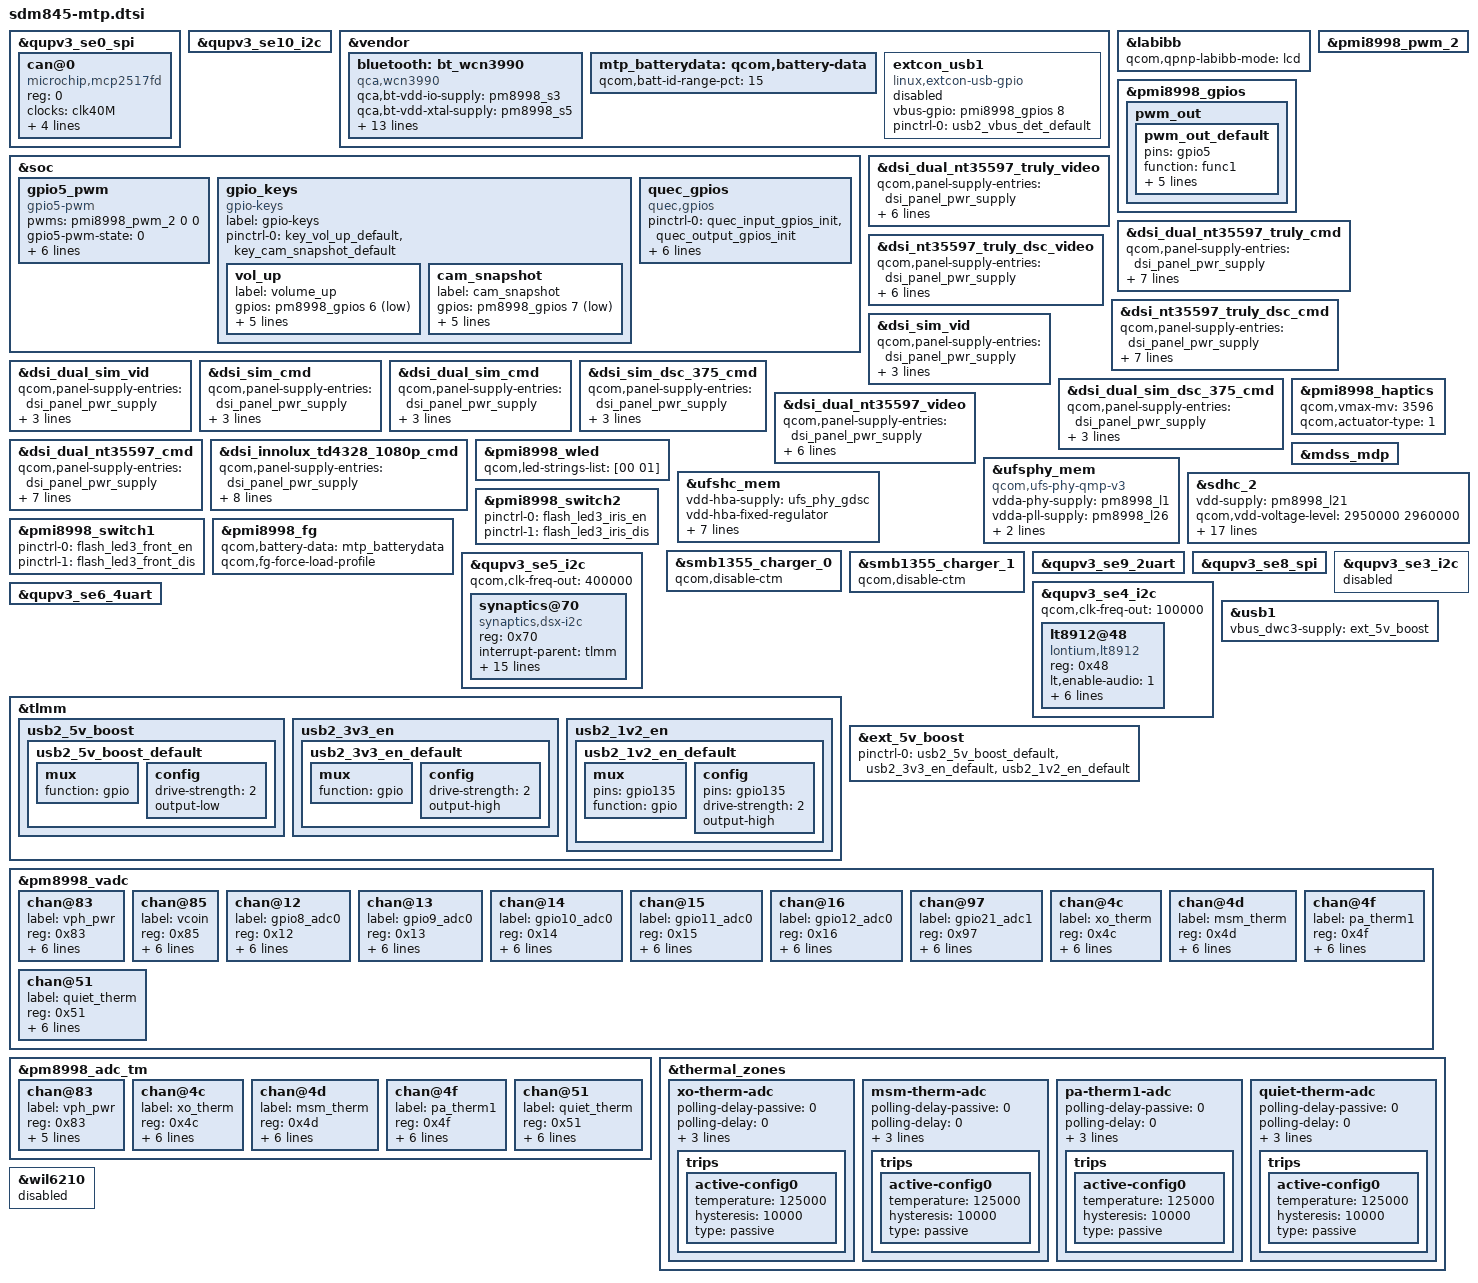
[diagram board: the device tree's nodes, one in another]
/* Copyright (c) 2016-2019, The Linux Foundation. All rights reserved.
 *
 * This program is free software; you can redistribute it and/or modify
 * it under the terms of the GNU General Public License version 2 and
 * only version 2 as published by the Free Software Foundation.
 *
 * This program is distributed in the hope that it will be useful,
 * but WITHOUT ANY WARRANTY; without even the implied warranty of
 * MERCHANTABILITY or FITNESS FOR A PARTICULAR PURPOSE.  See the
 * GNU General Public License for more details.
 */

#include <dt-bindings/gpio/gpio.h>
#include "sdm845-pmic-overlay.dtsi"
#include "sdm845-pinctrl-overlay.dtsi"
#include "sdm845-camera-sensor-mtp.dtsi"

&qupv3_se0_spi {
	status = "ok";
	can@0 {
		compatible = "microchip,mcp2517fd";
		reg = <0>;
		clocks = <&clk40M>;
		interrupt-parent = <&tlmm>;
		interrupts = <34 0>;
		interrupt-names = "can_irq";
		spi-max-frequency = <10000000>;
		gpio-controller;
		status = "okay";
	};
};

&qupv3_se10_i2c {
#include "smb1355.dtsi"
};

&vendor {
	bluetooth: bt_wcn3990 {
		compatible = "qca,wcn3990";
		qca,bt-vdd-io-supply = <&pm8998_s3>;
		qca,bt-vdd-xtal-supply = <&pm8998_s5>;
		qca,bt-vdd-core-supply = <&pm8998_l7>;
		qca,bt-vdd-pa-supply = <&pm8998_l17>;
		qca,bt-vdd-ldo-supply = <&pm8998_l25>;

		qca,bt-vdd-io-voltage-level = <1352000 1352000>;
		qca,bt-vdd-xtal-voltage-level = <2040000 2040000>;
		qca,bt-vdd-core-voltage-level = <1800000 1800000>;
		qca,bt-vdd-pa-voltage-level = <1304000 1304000>;
		qca,bt-vdd-ldo-voltage-level = <3312000 3312000>;

		qca,bt-vdd-io-current-level = <1>; /* LPM/PFM */
		qca,bt-vdd-xtal-current-level = <1>; /* LPM/PFM */
		qca,bt-vdd-core-current-level = <1>; /* LPM/PFM */
		qca,bt-vdd-pa-current-level = <1>; /* LPM/PFM */
		qca,bt-vdd-ldo-current-level = <1>; /* LPM/PFM */
	};
};

&soc {
	//zhounengwen@163.com begin
	gpio5_pwm {
		compatible = "gpio5-pwm";
		pwms = <&pmi8998_pwm_2 0 0>;
		gpio5-pwm-state = <0>;
		gpio5-pwm-duty-ns = <10000>;
		gpio5-pwm-period-ns = <50000>;
		qcom,fan-en-gpio = <&tlmm 44 0>;
		qcom,fan-fg-gpio = <&tlmm 30 0x2004>;
		pinctrl-names = "default";
		pinctrl-0 = <&pwm_out_default>;
		pinctrl-1 = <&fg_int_default>;
	};
	//zhounengwen@163.com end
	gpio_keys {
		compatible = "gpio-keys";
		label = "gpio-keys";

		pinctrl-names = "default";
		pinctrl-0 = <&key_vol_up_default
			     &key_cam_snapshot_default>;

		vol_up {
			label = "volume_up";
			gpios = <&pm8998_gpios 6 GPIO_ACTIVE_LOW>;
			linux,input-type = <1>;
			linux,code = <115>;
			gpio-key,wakeup;
			debounce-interval = <15>;
			linux,can-disable;
		};

		cam_snapshot {
			label = "cam_snapshot";
			gpios = <&pm8998_gpios 7 GPIO_ACTIVE_LOW>;
			linux,input-type = <1>;
			linux,code = <766>;
			gpio-key,wakeup;
			debounce-interval = <15>;
			linux,can-disable;
		};

		/*cam_focus {
			label = "cam_focus";
			gpios = <&pm8998_gpios 8 GPIO_ACTIVE_LOW>;
			linux,input-type = <1>;
			linux,code = <528>;
			gpio-key,wakeup;
			debounce-interval = <15>;
			linux,can-disable;
		};*/
	};
	
	quec_gpios {
		compatible = "quec,gpios";
		pinctrl-names = "default";
		pinctrl-0 = <&quec_input_gpios_init 
						&quec_output_gpios_init>;
		gpios = <&tlmm 0 0>,
			<&tlmm 3 0>,
			<&tlmm 7 1>,
			<&tlmm 22 0>,
			<&tlmm 24 0>,
			<&tlmm 25 1>,
			<&tlmm 26 0>,
			<&tlmm 40 0>,
			<&tlmm 41 0>,
			<&tlmm 49 0>,
			<&tlmm 52 0>,
			<&tlmm 87 1>,
			<&tlmm 91 0>,
			<&tlmm 92 0>,
			<&tlmm 95 0>,
			<&tlmm 96 0>,
			<&tlmm 116 0>,
			<&tlmm 122 0>,
			<&tlmm 124 0>,
			<&tlmm 128 0>,
			<&tlmm 129 1>;
	};
};

&labibb {
	status = "ok";
	qcom,qpnp-labibb-mode = "lcd";
};
//zhounengwen@163.com begin
&pmi8998_gpios {
    pwm_out {
        pwm_out_default: pwm_out_default {
            pins = "gpio5";
            function = "func1";
            bias-disable;
            power-source = <0>;
            output-low;
            qcom,drive-strength = <3>;
            drive-push-pull;
        };
    };
};

&pmi8998_pwm_2 {
    status = "okay";
    //qcom,force-pwm-size = <9>;
    //qcom,mode-select = <0>;
    //qcom,period = <100000>;
    //qcom,pwm {
    //    qcom,duty = <50000>;
    //    label = "pwm";
    //};
};
//zhounengwen@163.com end

&dsi_dual_nt35597_truly_video {
	qcom,panel-supply-entries = <&dsi_panel_pwr_supply>;
	qcom,mdss-dsi-bl-pmic-control-type = "bl_ctrl_wled";
	qcom,mdss-dsi-bl-min-level = <1>;
	qcom,mdss-dsi-bl-max-level = <4095>;
	qcom,mdss-dsi-mode-sel-gpio-state = "dual_port";
	//qcom,panel-mode-gpio = <&tlmm 52 0>;
	qcom,platform-reset-gpio = <&tlmm 6 0>;
};

&dsi_dual_nt35597_truly_cmd {
	qcom,panel-supply-entries = <&dsi_panel_pwr_supply>;
	qcom,mdss-dsi-bl-pmic-control-type = "bl_ctrl_wled";
	qcom,mdss-dsi-bl-min-level = <1>;
	qcom,mdss-dsi-bl-max-level = <4095>;
	qcom,mdss-dsi-mode-sel-gpio-state = "dual_port";
	//qcom,panel-mode-gpio = <&tlmm 52 0>;
	qcom,platform-reset-gpio = <&tlmm 6 0>;
	qcom,platform-te-gpio = <&tlmm 10 0>;
};

&dsi_nt35597_truly_dsc_video {
	qcom,panel-supply-entries = <&dsi_panel_pwr_supply>;
	qcom,mdss-dsi-bl-pmic-control-type = "bl_ctrl_wled";
	qcom,mdss-dsi-bl-min-level = <1>;
	qcom,mdss-dsi-bl-max-level = <4095>;
	qcom,mdss-dsi-mode-sel-gpio-state = "single_port";
	//qcom,panel-mode-gpio = <&tlmm 52 0>;
	qcom,platform-reset-gpio = <&tlmm 6 0>;
};

&dsi_nt35597_truly_dsc_cmd {
	qcom,panel-supply-entries = <&dsi_panel_pwr_supply>;
	qcom,mdss-dsi-bl-pmic-control-type = "bl_ctrl_wled";
	qcom,mdss-dsi-bl-min-level = <1>;
	qcom,mdss-dsi-bl-max-level = <4095>;
	qcom,mdss-dsi-mode-sel-gpio-state = "single_port";
	//qcom,panel-mode-gpio = <&tlmm 52 0>;
	qcom,platform-reset-gpio = <&tlmm 6 0>;
	qcom,platform-te-gpio = <&tlmm 10 0>;
};

&dsi_sim_vid {
	qcom,panel-supply-entries = <&dsi_panel_pwr_supply>;
	qcom,mdss-dsi-bl-pmic-control-type = "bl_ctrl_wled";
	qcom,platform-reset-gpio = <&tlmm 6 0>;
};

&dsi_dual_sim_vid {
	qcom,panel-supply-entries = <&dsi_panel_pwr_supply>;
	qcom,mdss-dsi-bl-pmic-control-type = "bl_ctrl_wled";
	qcom,platform-reset-gpio = <&tlmm 6 0>;
};

&dsi_sim_cmd {
	qcom,panel-supply-entries = <&dsi_panel_pwr_supply>;
	qcom,mdss-dsi-bl-pmic-control-type = "bl_ctrl_wled";
	qcom,platform-reset-gpio = <&tlmm 6 0>;
};

&dsi_dual_sim_cmd {
	qcom,panel-supply-entries = <&dsi_panel_pwr_supply>;
	qcom,mdss-dsi-bl-pmic-control-type = "bl_ctrl_wled";
	qcom,platform-reset-gpio = <&tlmm 6 0>;
};

&dsi_sim_dsc_375_cmd {
	qcom,panel-supply-entries = <&dsi_panel_pwr_supply>;
	qcom,mdss-dsi-bl-pmic-control-type = "bl_ctrl_wled";
	qcom,platform-reset-gpio = <&tlmm 6 0>;
};

&dsi_dual_sim_dsc_375_cmd {
	qcom,panel-supply-entries = <&dsi_panel_pwr_supply>;
	qcom,mdss-dsi-bl-pmic-control-type = "bl_ctrl_wled";
	qcom,platform-reset-gpio = <&tlmm 6 0>;
};

&dsi_dual_nt35597_video {
	qcom,panel-supply-entries = <&dsi_panel_pwr_supply>;
	qcom,mdss-dsi-bl-pmic-control-type = "bl_ctrl_wled";
	qcom,mdss-dsi-bl-min-level = <1>;
	qcom,mdss-dsi-bl-max-level = <4095>;
	qcom,mdss-dsi-mode-sel-gpio-state = "dual_port";
	//qcom,panel-mode-gpio = <&tlmm 52 0>;
	qcom,platform-reset-gpio = <&tlmm 6 0>;
};

&dsi_dual_nt35597_cmd {
	qcom,panel-supply-entries = <&dsi_panel_pwr_supply>;
	qcom,mdss-dsi-bl-pmic-control-type = "bl_ctrl_wled";
	qcom,mdss-dsi-bl-min-level = <1>;
	qcom,mdss-dsi-bl-max-level = <4095>;
	qcom,mdss-dsi-mode-sel-gpio-state = "dual_port";
	//qcom,panel-mode-gpio = <&tlmm 52 0>;
	qcom,platform-reset-gpio = <&tlmm 6 0>;
	qcom,platform-te-gpio = <&tlmm 10 0>;
};

&dsi_innolux_td4328_1080p_cmd {
	qcom,panel-supply-entries = <&dsi_panel_pwr_supply>;
	qcom,mdss-dsi-bl-pmic-control-type = "bl_ctrl_wled";
	qcom,mdss-dsi-bl-min-level = <1>;
	qcom,mdss-dsi-bl-max-level = <4095>;
	qcom,mdss-dsi-mode-sel-gpio-state = "single_port";
	qcom,5v-boost-gpio = <&tlmm 120 0>;
	qcom,platform-reset-gpio = <&tlmm 6 0>;
	qcom,platform-te-gpio = <&tlmm 10 0>;
};
/*
&dsi_nt35597_truly_dsc_cmd_display {
	qcom,dsi-display-active;
};
*/
&pmi8998_wled {
	status = "okay";
	qcom,led-strings-list = [00 01];
};

&pmi8998_haptics {
	qcom,vmax-mv = <3596>;
	//qcom,lra-auto-mode;
	qcom,actuator-type = <1>;
	status = "okay";
};

&mdss_mdp {
	#cooling-cells = <2>;
};

&ufsphy_mem {
	compatible = "qcom,ufs-phy-qmp-v3";

	vdda-phy-supply = <&pm8998_l1>; /* 0.88v */
	vdda-pll-supply = <&pm8998_l26>; /* 1.2v */
	vdda-phy-max-microamp = <62900>;
	vdda-pll-max-microamp = <18300>;

	status = "ok";
};

&ufshc_mem {
	vdd-hba-supply = <&ufs_phy_gdsc>;
	vdd-hba-fixed-regulator;
	vcc-supply = <&pm8998_l20>;
	vcc-voltage-level = <2950000 2960000>;
	vccq2-supply = <&pm8998_s4>;
	vcc-max-microamp = <600000>;
	vccq2-max-microamp = <600000>;

	qcom,vddp-ref-clk-supply = <&pm8998_l2>;
	qcom,vddp-ref-clk-max-microamp = <100>;

	status = "ok";
};

&sdhc_2 {
	vdd-supply = <&pm8998_l21>;
	qcom,vdd-voltage-level = <2950000 2960000>;
	qcom,vdd-current-level = <200 800000>;

	vdd-io-supply = <&pm8998_l13>;
	qcom,vdd-io-voltage-level = <1808000 2960000>;
	qcom,vdd-io-current-level = <200 22000>;

	pinctrl-names = "active", "sleep", "ds_400KHz",
			"ds_50MHz", "ds_100MHz", "ds_200MHz";
	pinctrl-0 = <&sdc2_clk_on  &sdc2_cmd_on &sdc2_data_on &storage_cd>;
	pinctrl-1 = <&sdc2_clk_off &sdc2_cmd_off &sdc2_data_off &storage_cd>;
	pinctrl-2 = <&sdc2_clk_ds_400KHz
			&sdc2_cmd_ds_400KHz &sdc2_data_ds_400KHz>;
	pinctrl-3 = <&sdc2_clk_ds_50MHz
			&sdc2_cmd_ds_50MHz &sdc2_data_ds_50MHz>;
	pinctrl-4 = <&sdc2_clk_ds_100MHz
			&sdc2_cmd_ds_100MHz &sdc2_data_ds_100MHz>;
	pinctrl-5 = <&sdc2_clk_ds_200MHz
			&sdc2_cmd_ds_200MHz &sdc2_data_ds_200MHz>;

	cd-gpios = <&tlmm 126 GPIO_ACTIVE_LOW>;

	status = "ok";
};

&pmi8998_switch1 {
	pinctrl-names = "led_enable", "led_disable";
	pinctrl-0 = <&flash_led3_front_en>;
	pinctrl-1 = <&flash_led3_front_dis>;
};

&pmi8998_switch2 {
	pinctrl-names = "led_enable", "led_disable";
	pinctrl-0 = <&flash_led3_iris_en>;
	pinctrl-1 = <&flash_led3_iris_dis>;
};

&vendor {
	mtp_batterydata: qcom,battery-data {
		qcom,batt-id-range-pct = <15>;
		//#include "fg-gen3-batterydata-itech-3000mah.dtsi"
		//#include "fg-gen3-batterydata-ascent-3450mah.dtsi"
		//#include "fg-gen3-batterydata-chijin-5000mah.dtsi"
		#include "fg-gen3-batterydata-chijin-6600mah.dtsi"
	};

	extcon_usb1: extcon_usb1 {
		compatible = "linux,extcon-usb-gpio";
		vbus-gpio = <&pmi8998_gpios 8 GPIO_ACTIVE_HIGH>;

		pinctrl-names = "default";
		pinctrl-0 = <&usb2_vbus_det_default>;
		status = "disabled";
	};
};

&pmi8998_fg {
	qcom,battery-data = <&mtp_batterydata>;
	qcom,fg-force-load-profile;
};

&smb1355_charger_0 {
	status = "ok";
	qcom,disable-ctm;
};

&smb1355_charger_1 {
	status = "ok";
	qcom,disable-ctm;
};

&qupv3_se9_2uart {
	status = "ok";
};

&qupv3_se8_spi {
	status = "ok";
};

/*
&qupv3_se7_i2c {
	status = "ok";
	ads7830@48 {
		compatible = "ads7830";
		reg = <0x48>;
	};
};
*/
&qupv3_se3_i2c {
	status = "disabled";
	/*nq@28 {
		compatible = "qcom,nq-nci";
		reg = <0x28>;
		qcom,nq-irq = <&tlmm 63 0x00>;
		qcom,nq-ven = <&tlmm 12 0x00>;
		qcom,nq-firm = <&tlmm 62 0x00>;
		qcom,nq-clkreq = <&pm8998_gpios 21 0x00>;
		//qcom,nq-esepwr = <&tlmm 116 0x00>;
		interrupt-parent = <&tlmm>;
		interrupts = <63 0>;
		interrupt-names = "nfc_irq";
		pinctrl-names = "nfc_active", "nfc_suspend";
		pinctrl-0 = <&nfc_int_active
			     &nfc_enable_active
			     &nfc_clk_default>;
		pinctrl-1 = <&nfc_int_suspend &nfc_enable_suspend>;
	};*/
};

&qupv3_se5_i2c {
	status = "ok";
	qcom,clk-freq-out = <400000>;
	synaptics@70 {
		compatible = "synaptics,dsx-i2c";
		reg = <0x70>;
		interrupt-parent = <&tlmm>;
		interrupts = <125 0x2>;
		pinctrl-names = "pmx_ts_active", "pmx_ts_suspend";
		pinctrl-0 = <&ts_int_active &ts_reset_active>;
		pinctrl-1 = <&ts_int_suspend &ts_reset_suspend>;
		vdd_ana-supply = <&pm8998_l28>;
		vcc_i2c-supply  = <&pm8998_l14>;
		synaptics,pwr-reg-name = "vdd_ana";
		synaptics,bus-reg-name = "vcc_i2c";
		synaptics,ub-i2c-addr = <0x20>;
		/* IRQF_ONESHOT | IRQF_TRIGGER_LOW */
		synaptics,irq-gpio = <&tlmm 125 0x2008>;
		synaptics,irq-on-state = <0>;
		synaptics,reset-gpio = <&tlmm 104 0>;	//hrb
		synaptics,power-delay-ms = <200>;
		synaptics,reset-delay-ms = <200>;
		synaptics,reset-on-state = <0>;
		synaptics,reset-active-ms = <20>;

	};
};
//zhounengwen@163.com begin
&qupv3_se4_i2c {
	status = "ok";
	qcom,clk-freq-out = <100000>;
	lt8912@48 {
		compatible = "lontium,lt8912";
		status = "okay";
		reg = <0x48>;
		lt,enable-audio = <1>;
		lt,pwren-gpio = <&tlmm 8 0x00>;
		lt,reset-gpio = <&tlmm 12 0x00>;
		lt,hdmien-gpio = <&tlmm 13 0x00>;
		lt,hdmidet-gpio = <&tlmm 121 0x00>;
		pinctrl-names = "hdmidet_active","hdmidet_suspend";
		pinctrl-0 = <&hdmi_det_active>;
		pinctrl-1 = <&hdmi_det_suspend>;
		//lt,hpd-gpio = <&tlmm 9 0x00>;
		//interrupt-parent = <&tlmm>;
		//interrupts = <9 0>;
		//interrupt-names = "hdmi_hpd_irq1";
	};
};
//zhounengwen@163.com end
&qupv3_se10_i2c {
	status = "ok";
};

&qupv3_se6_4uart {
	status = "ok";
};

&tlmm {
	usb2_5v_boost {
		usb2_5v_boost_default: usb2_5v_boost_default  {
			mux {
				//pins = "gpio129";
				function = "gpio";
			};

			config {
				//pins = "gpio129";         
				drive-strength = <2>;  
				output-low;  
			};
		};
	};
	
	usb2_3v3_en {
		usb2_3v3_en_default: usb2_3v3_en_default  {
			mux {
				//pins = "gpio128";
				function = "gpio";
			};

			config {
				//pins = "gpio128";         
				drive-strength = <2>;  
				output-high;  
			};
		};
	};

	usb2_1v2_en {
		usb2_1v2_en_default: usb2_1v2_en_default  {
			mux {
				pins = "gpio135";
				function = "gpio";
			};

			config {
				pins = "gpio135";         
				drive-strength = <2>;  
				output-high;  
			};
		};
	};
};

&ext_5v_boost {
	status = "ok";
	//gpio = <&tlmm 129 GPIO_ACTIVE_HIGH>;
	pinctrl-names = "default";
	pinctrl-0 = <&usb2_5v_boost_default
	             &usb2_3v3_en_default
				 &usb2_1v2_en_default>;
};

&usb1 {
     status = "ok";
	//extcon = <&extcon_usb1>;
	vbus_dwc3-supply = <&ext_5v_boost>;
};

&pm8998_vadc {
	chan@83 {
		label = "vph_pwr";
		reg = <0x83>;
		qcom,decimation = <2>;
		qcom,pre-div-channel-scaling = <1>;
		qcom,calibration-type = "absolute";
		qcom,scale-function = <0>;
		qcom,hw-settle-time = <0>;
		qcom,fast-avg-setup = <0>;
	};

	chan@85 {
		label = "vcoin";
		reg = <0x85>;
		qcom,decimation = <2>;
		qcom,pre-div-channel-scaling = <1>;
		qcom,calibration-type = "absolute";
		qcom,scale-function = <0>;
		qcom,hw-settle-time = <0>;
		qcom,fast-avg-setup = <0>;
	};

	chan@12 {
		label = "gpio8_adc0";
		reg = <0x12>;
		qcom,decimation = <0>;
		qcom,pre-div-channel-scaling = <0>;
		qcom,calibration-type = "absolute";
		qcom,scale-function = <0>;
		qcom,hw-settle-time = <0>;
		qcom,fast-avg-setup = <0>;
	};
	
	chan@13 {
		label = "gpio9_adc0";
		reg = <0x13>;
		qcom,decimation = <0>;
		qcom,pre-div-channel-scaling = <0>;
		qcom,calibration-type = "absolute";
		qcom,scale-function = <0>;
		qcom,hw-settle-time = <0>;
		qcom,fast-avg-setup = <0>;
	};
	
	chan@14 {
		label = "gpio10_adc0";
		reg = <0x14>;
		qcom,decimation = <0>;
		qcom,pre-div-channel-scaling = <0>;
		qcom,calibration-type = "absolute";
		qcom,scale-function = <0>;
		qcom,hw-settle-time = <0>;
		qcom,fast-avg-setup = <0>;
	};
	
	chan@15 {
		label = "gpio11_adc0";
		reg = <0x15>;
		qcom,decimation = <0>;
		qcom,pre-div-channel-scaling = <0>;
		qcom,calibration-type = "absolute";
		qcom,scale-function = <0>;
		qcom,hw-settle-time = <0>;
		qcom,fast-avg-setup = <0>;
	};
	
	chan@16 {
		label = "gpio12_adc0";
		reg = <0x16>;
		qcom,decimation = <0>;
		qcom,pre-div-channel-scaling = <0>;
		qcom,calibration-type = "absolute";
		qcom,scale-function = <0>;
		qcom,hw-settle-time = <0>;
		qcom,fast-avg-setup = <0>;
	};
	
	chan@97 {
		label = "gpio21_adc1";
		reg = <0x97>;
		qcom,decimation = <0>;
		qcom,pre-div-channel-scaling = <1>;
		qcom,calibration-type = "absolute";
		qcom,scale-function = <0>;
		qcom,hw-settle-time = <0>;
		qcom,fast-avg-setup = <0>;
	};
	
	chan@4c {
		label = "xo_therm";
		reg = <0x4c>;
		qcom,decimation = <2>;
		qcom,pre-div-channel-scaling = <0>;
		qcom,calibration-type = "ratiometric";
		qcom,scale-function = <4>;
		qcom,hw-settle-time = <2>;
		qcom,fast-avg-setup = <0>;
	};

	chan@4d {
		label = "msm_therm";
		reg = <0x4d>;
		qcom,decimation = <2>;
		qcom,pre-div-channel-scaling = <0>;
		qcom,calibration-type = "ratiometric";
		qcom,scale-function = <2>;
		qcom,hw-settle-time = <2>;
		qcom,fast-avg-setup = <0>;
	};

	chan@4f {
		label = "pa_therm1";
		reg = <0x4f>;
		qcom,decimation = <2>;
		qcom,pre-div-channel-scaling = <0>;
		qcom,calibration-type = "ratiometric";
		qcom,scale-function = <2>;
		qcom,hw-settle-time = <2>;
		qcom,fast-avg-setup = <0>;
	};

	chan@51 {
		label = "quiet_therm";
		reg = <0x51>;
		qcom,decimation = <2>;
		qcom,pre-div-channel-scaling = <0>;
		qcom,calibration-type = "ratiometric";
		qcom,scale-function = <2>;
		qcom,hw-settle-time = <2>;
		qcom,fast-avg-setup = <0>;
	};
};

&pm8998_adc_tm {
	chan@83 {
		label = "vph_pwr";
		reg = <0x83>;
		qcom,pre-div-channel-scaling = <1>;
		qcom,calibration-type = "absolute";
		qcom,scale-function = <0>;
		qcom,hw-settle-time = <0>;
		qcom,btm-channel-number = <0x60>;
	};

	chan@4c {
		label = "xo_therm";
		reg = <0x4c>;
		qcom,pre-div-channel-scaling = <0>;
		qcom,calibration-type = "ratiometric";
		qcom,scale-function = <4>;
		qcom,hw-settle-time = <2>;
		qcom,btm-channel-number = <0x68>;
		qcom,thermal-node;
	};

	chan@4d {
		label = "msm_therm";
		reg = <0x4d>;
		qcom,pre-div-channel-scaling = <0>;
		qcom,calibration-type = "ratiometric";
		qcom,scale-function = <2>;
		qcom,hw-settle-time = <2>;
		qcom,btm-channel-number = <0x70>;
		qcom,thermal-node;
	};

	chan@4f {
		label = "pa_therm1";
		reg = <0x4f>;
		qcom,pre-div-channel-scaling = <0>;
		qcom,calibration-type = "ratiometric";
		qcom,scale-function = <2>;
		qcom,hw-settle-time = <2>;
		qcom,btm-channel-number = <0x78>;
		qcom,thermal-node;
	};

	chan@51 {
		label = "quiet_therm";
		reg = <0x51>;
		qcom,pre-div-channel-scaling = <0>;
		qcom,calibration-type = "ratiometric";
		qcom,scale-function = <2>;
		qcom,hw-settle-time = <2>;
		qcom,btm-channel-number = <0x80>;
		qcom,thermal-node;
	};
};

&thermal_zones {
	xo-therm-adc {
		polling-delay-passive = <0>;
		polling-delay = <0>;
		thermal-sensors = <&pm8998_adc_tm 0x4c>;
		wake-capable-sensor;
		thermal-governor = "user_space";

		trips {
			active-config0 {
				temperature = <125000>;
				hysteresis = <10000>;
				type = "passive";
			};
		};
	};

	msm-therm-adc {
		polling-delay-passive = <0>;
		polling-delay = <0>;
		thermal-sensors = <&pm8998_adc_tm 0x4d>;
		wake-capable-sensor;
		thermal-governor = "user_space";

		trips {
			active-config0 {
				temperature = <125000>;
				hysteresis = <10000>;
				type = "passive";
			};
		};
	};

	pa-therm1-adc {
		polling-delay-passive = <0>;
		polling-delay = <0>;
		thermal-sensors = <&pm8998_adc_tm 0x4f>;
		wake-capable-sensor;
		thermal-governor = "user_space";

		trips {
			active-config0 {
				temperature = <125000>;
				hysteresis = <10000>;
				type = "passive";
			};
		};
	};

	quiet-therm-adc {
		polling-delay-passive = <0>;
		polling-delay = <0>;
		thermal-sensors = <&pm8998_adc_tm 0x51>;
		wake-capable-sensor;
		thermal-governor = "user_space";

		trips {
			active-config0 {
				temperature = <125000>;
				hysteresis = <10000>;
				type = "passive";
			};
		};
	};
};

&wil6210 {
	status = "disabled";
};
